# M344 register map
File version: 2.0.2.6
Registers are 32-bit, read-write, reset 0x0 unless marked. A register's access mark holds for its fields unless they carry their own. Offsets are from the block's base; [hi:lo] are bit positions; {n}, {i} and the like mark numbered series.

## SBI — Serial Bus Interface (SBI)
Base 0x400E0000
0x00 CR0 — SBI Control Register 0
  [7] SBIEN
0x04 CR1_A reset 0x3 — SBI Control Register 1 (I2C Mode)
  [7:5] BC, [4] ACK, [0] SWRMON ro, [2:0] SCK wo
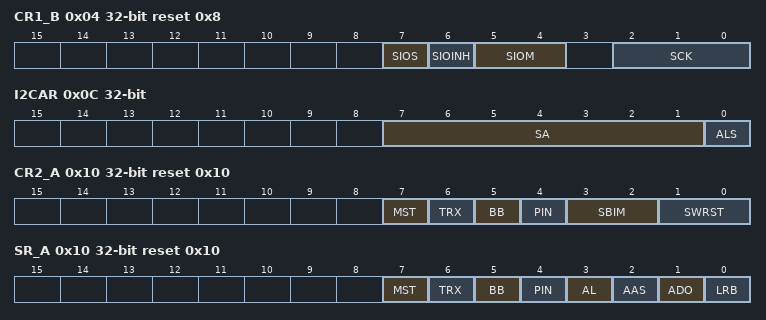
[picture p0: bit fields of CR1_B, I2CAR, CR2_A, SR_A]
0x04 CR1_B reset 0x8 (SBI_CR1 view) — SBI Control Register 1 (SIO Mode)
  [7] SIOS, [6] SIOINH, [5:4] SIOM, [2:0] SCK
0x08 DBR — SBI Data Buffer Register
  [7:0] DB
0x0C I2CAR — SBI I2C Bus Address Register
  [7:1] SA, [0] ALS
0x10 CR2_A wo reset 0x10 — SBI Control Register 2 (I2C Mode)
  [7] MST, [6] TRX, [5] BB, [4] PIN, [3:2] SBIM, [1:0] SWRST
0x10 CR2_B wo reset 0xF3 (SBI_CR2 view) — SBI Control Register 2 (SIO Mode)
  [3:2] SBIM
0x10 SR_A ro reset 0x10 — SBI Status Register (I2C Mode)
  [7] MST, [6] TRX, [5] BB, [4] PIN, [3] AL, [2] AAS, [1] ADO, [0] LRB
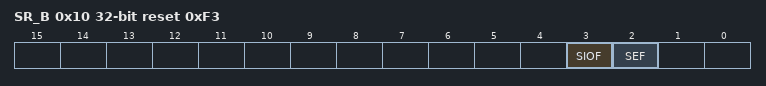
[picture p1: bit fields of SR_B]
0x10 SR_B ro reset 0xF3 (SBI_SR view) — SBI Status Register (SIO Mode)
  [3] SIOF, [2] SEF
0x14 BR0 reset 0xBE — SBI Baud Rate Register 0
  [6] I2SBI

## SC — Serial Channel (SC)
Base 0x400E1000
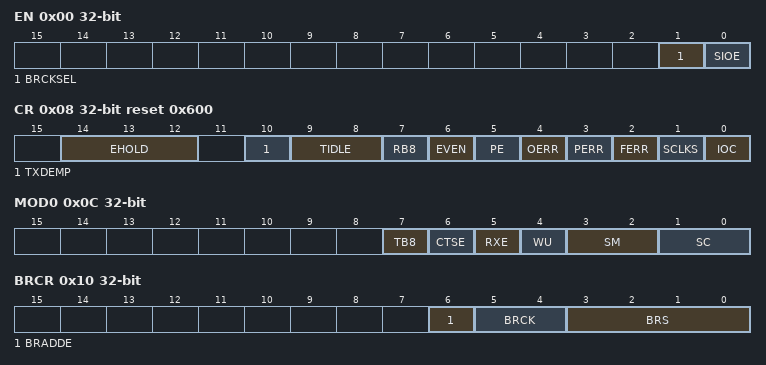
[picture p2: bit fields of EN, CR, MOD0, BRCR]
0x00 EN — SC Enable Register
  [1] BRCKSEL, [0] SIOE
0x04 BUF — SC Buffer Register
  [7:0] TB_RB
0x08 CR reset 0x600 — SC Control Register
  [14:12] EHOLD, [10] TXDEMP, [9:8] TIDLE, [7] RB8 ro, [6] EVEN, [5] PE, [4] OERR ro, [3] PERR ro, [2] FERR ro, [1] SCLKS, [0] IOC
0x0C MOD0 — SC Mode Control Register 0
  [7] TB8, [6] CTSE, [5] RXE, [4] WU, [3:2] SM, [1:0] SC
0x10 BRCR — SC Baud Rate Generator Control Register
  [6] BRADDE, [5:4] BRCK, [3:0] BRS
0x14 BRADD — SC Baud Rate Generator Control Register 2
  [3:0] BRK
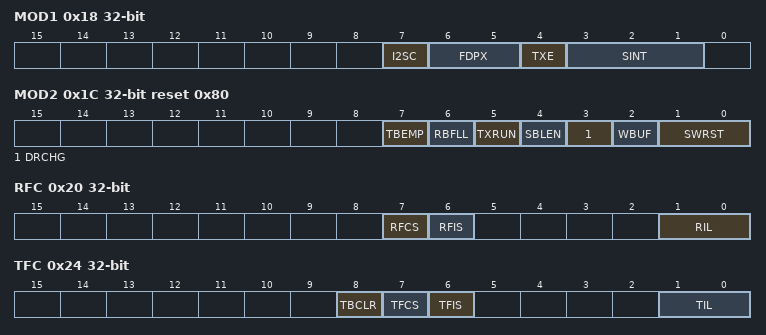
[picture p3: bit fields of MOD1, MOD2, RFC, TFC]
0x18 MOD1 — SC Mode Control Register 1
  [7] I2SC, [6:5] FDPX, [4] TXE, [3:1] SINT
0x1C MOD2 reset 0x80 — SC Mode Control Register 2
  [7] TBEMP ro, [6] RBFLL ro, [5] TXRUN ro, [4] SBLEN, [3] DRCHG, [2] WBUF, [1:0] SWRST
0x20 RFC — SC RX FIFO Configuration Register
  [7] RFCS wo, [6] RFIS, [1:0] RIL
0x24 TFC — SC TX FIFO Configuration Register
  [8] TBCLR, [7] TFCS, [6] TFIS, [1:0] TIL
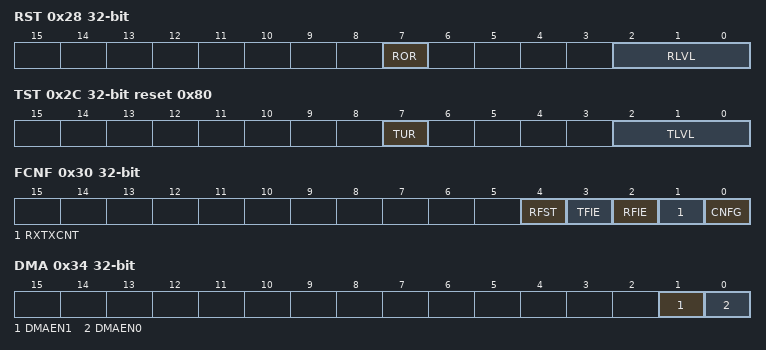
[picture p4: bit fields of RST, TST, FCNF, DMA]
0x28 RST ro — SC RX FIFO Status Register
  [7] ROR, [2:0] RLVL
0x2C TST ro reset 0x80 — SC TX FIFO Status Register
  [7] TUR, [2:0] TLVL
0x30 FCNF — SC FIFO Configuration Register
  [4] RFST, [3] TFIE, [2] RFIE, [1] RXTXCNT, [0] CNFG
0x34 DMA — SC DMA Request Enable Register
  [1] DMAEN1, [0] DMAEN0

## WD — Watchdog Timer (WD)
Base 0x400F2000
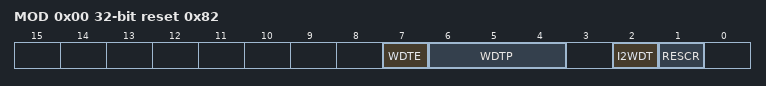
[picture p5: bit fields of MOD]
0x00 MOD reset 0x82 — WD Mode Register
  [7] WDTE, [6:4] WDTP, [2] I2WDT, [1] RESCR
0x04 CR wo (reset mask 0xFFFFFF00) — WD Control Register
  [7:0] WDCR

## CG — Clock Generator (CG)
Base 0x400F3000
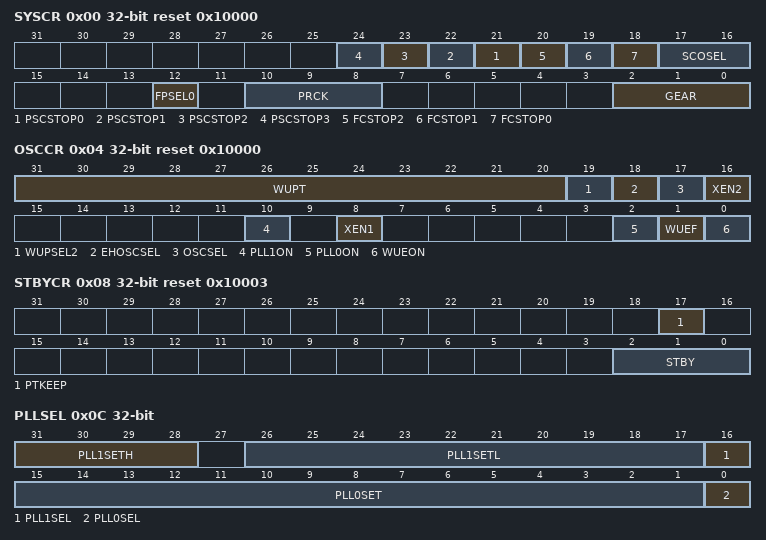
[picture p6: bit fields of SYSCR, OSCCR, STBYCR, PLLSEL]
0x00 SYSCR reset 0x10000 — System Control Register
  [n+21] PSCSTOP{n} (n=0..3), [20] FCSTOP2, [19] FCSTOP1, [18] FCSTOP0, [17:16] SCOSEL, [12] FPSEL0, [10:8] PRCK, [2:0] GEAR
0x04 OSCCR reset 0x10000 — Oscillation Control Register
  [31:20] WUPT, [19] WUPSEL2, [18] EHOSCSEL, [17] OSCSEL, [16] XEN2, [10] PLL1ON, [8] XEN1, [2] PLL0ON, [1] WUEF ro, [0] WUEON wo
0x08 STBYCR reset 0x10003 — Standby Control Register
  [17] PTKEEP, [2:0] STBY
0x0C PLLSEL — PLL Selection Register
  [31:28] PLL1SETH, [26:17] PLL1SETL, [16] PLL1SEL, [15:1] PLL0SET, [0] PLL0SEL
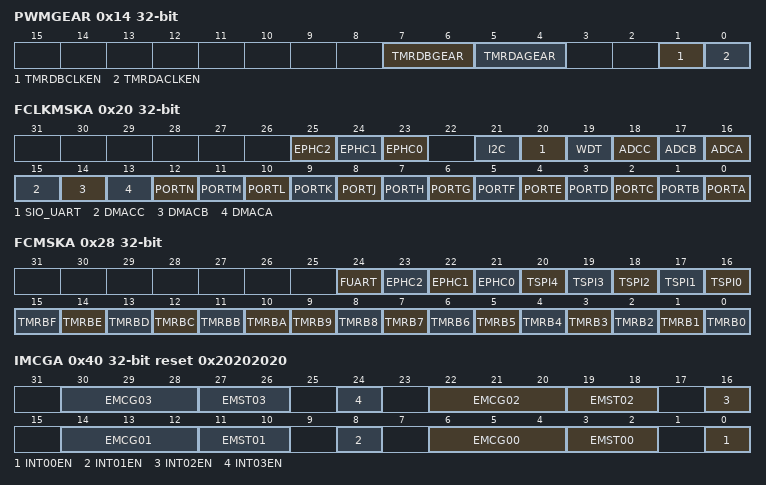
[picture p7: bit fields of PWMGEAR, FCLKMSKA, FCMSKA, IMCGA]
0x14 PWMGEAR — Timer D Clock Setting Register
  [7:6] TMRDBGEAR, [5:4] TMRDAGEAR, [1] TMRDBCLKEN, [0] TMRDACLKEN
0x20 FCLKMSKA — fclk Supply Stop Register A
  [25] EPHC2, [24] EPHC1, [23] EPHC0, [21] I2C, [20] SIO_UART, [19] WDT, [18] ADCC, [17] ADCB, [16] ADCA, [15] DMACC, [14] DMACB, [13] DMACA, [12] PORTN, [11] PORTM, [10] PORTL, [9] PORTK, [8] PORTJ, [7] PORTH, [6] PORTG, [5] PORTF, [4] PORTE, [3] PORTD, [2] PORTC, [1] PORTB, [0] PORTA
0x28 FCMSKA — fc Supply Stop Register A
  [24] FUART, [23] EPHC2, [22] EPHC1, [21] EPHC0, [n+16] TSPI{n} (n=0..4), [15] TMRBF, [14] TMRBE, [13] TMRBD, [12] TMRBC, [11] TMRBB, [10] TMRBA, [n] TMRB{n} (n=0..9)
0x3C PROTECT reset 0xC1
  [7:0] CGPROTECT
0x40 IMCGA reset 0x20202020 — CG Interrupt Mode Control Register A
  [8n+6:8n+4] EMCG{n:02} (n=0..3), [8n+3:8n+2] EMST{n:02} ro (n=0..3), [8n] INT{n:02}EN (n=0..3)
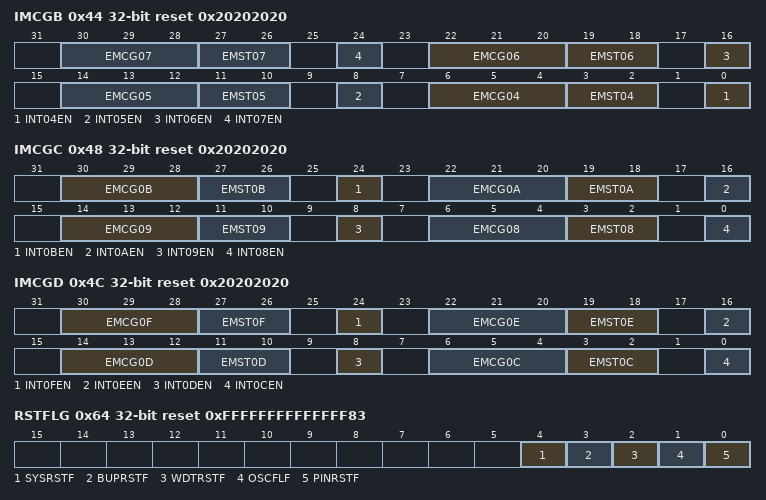
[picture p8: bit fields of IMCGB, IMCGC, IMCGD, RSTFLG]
0x44 IMCGB reset 0x20202020 — CG Interrupt Mode Control Register B
  [8n-26:8n-28] EMCG{n:02} (n=4..7), [8n-29:8n-30] EMST{n:02} ro (n=4..7), [8n-32] INT{n:02}EN (n=4..7)
0x48 IMCGC reset 0x20202020 — CG Interrupt Mode Control Register C
  [30:28] EMCG0B, [27:26] EMST0B ro, [24] INT0BEN, [22:20] EMCG0A, [19:18] EMST0A ro, [16] INT0AEN, [14:12] EMCG09, [11:10] EMST09 ro, [8] INT09EN, [6:4] EMCG08, [3:2] EMST08 ro, [0] INT08EN
0x4C IMCGD reset 0x20202020 — CG Interrupt Mode Control Register D
  [30:28] EMCG0F, [27:26] EMST0F ro, [24] INT0FEN, [22:20] EMCG0E, [19:18] EMST0E ro, [16] INT0EEN, [14:12] EMCG0D, [11:10] EMST0D ro, [8] INT0DEN, [6:4] EMCG0C, [3:2] EMST0C ro, [0] INT0CEN
0x60 ICRCG wo — CG Interrupt Request Clear Register
  [3:0] ICRCG
0x64 RSTFLG reset 0xFFFFFFFFFFFFFF83 — Reset Flag Register
  [4] SYSRSTF, [3] BUPRSTF, [2] WDTRSTF, [1] OSCFLF ro, [0] PINRSTF
0x68 NMIFLG ro — NMI Flag Register
  [0] NMIFLG0

## FC — Flash Control (FC)
Base 0x5DFF0000
0x10 SECBIT reset 0x1 — Security Bit Register
  [0] SECBIT
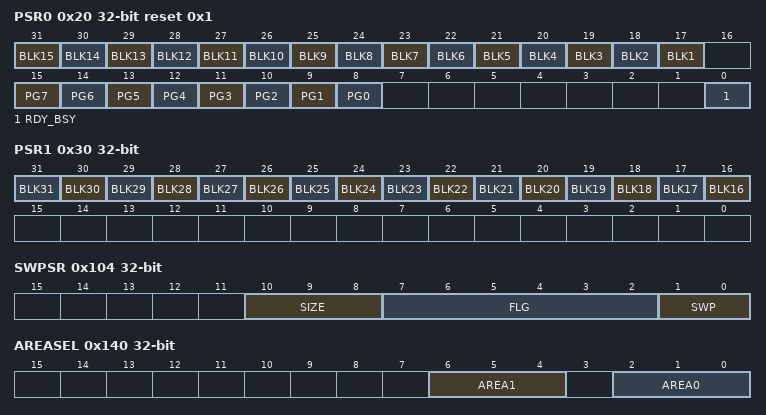
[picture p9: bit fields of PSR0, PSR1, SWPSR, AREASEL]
0x20 PSR0 ro reset 0x1 (reset mask 0xFF) — Protect Status Register 0
  [n+16] BLK{n} (n=1..15), [n+8] PG{n} (n=0..7), [0] RDY_BSY
0x30 PSR1 ro (reset mask 0xFFFE) — Protect Status Register 1
  [n] BLK{n} (n=16..31)
0x100 SR ro reset 0x1 — Status Register
  [24] WEABORT
0x104 SWPSR ro (reset mask 0xFFFFF800) — Swap Status Register
  [10:8] SIZE, [7:2] FLG, [1:0] SWP
0x140 AREASEL — Area Selection Register
  [6:4] AREA1, [2:0] AREA0
0x148 CR — Control Register
  [2:0] WEABORT
0x14C STSCLR — Status Clear Register
  [2:0] WEABORT
0x150 WCLKCR — WCLK Configuration Register
  [4:0] DIV
0x154 PROGCR reset 0x1 — Program Counter Configuration Register
  [1:0] CNT
0x158 ERASECR reset 0x6 — Erase Counter Configuration Register
  [3:0] CNT
